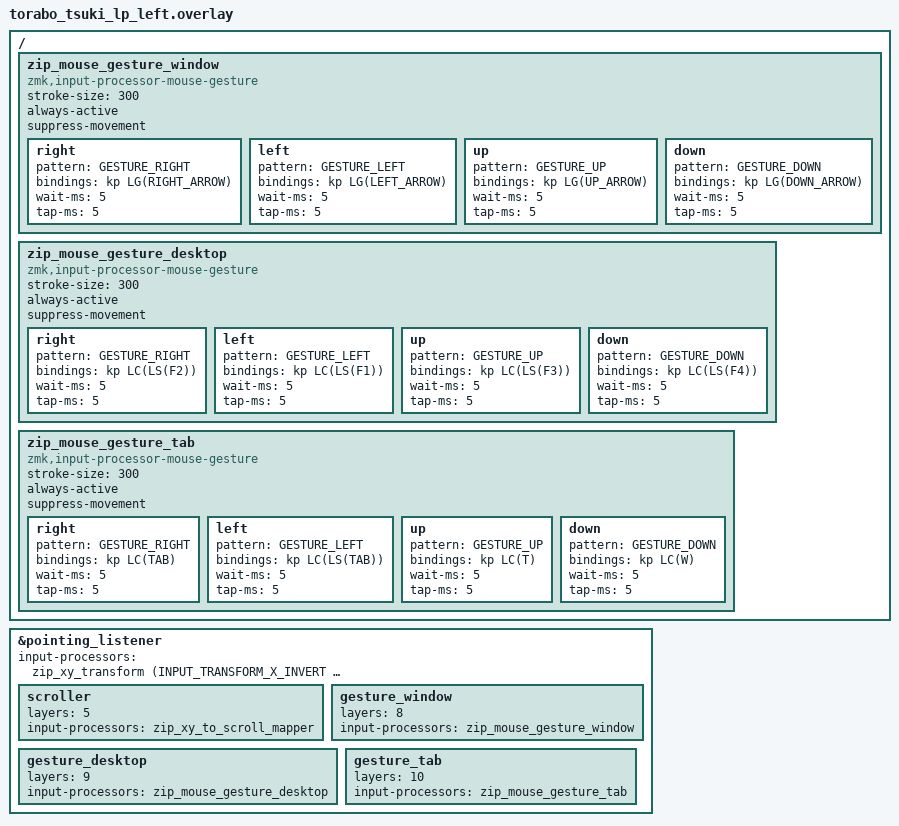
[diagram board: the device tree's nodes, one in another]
#include "torabo_tsuki_lp.dtsi"
#include <input/processors.dtsi>
#include <dt-bindings/zmk/input_transform.h>
#include <dt-bindings/zmk/mouse-gesture.h>
#include <dt-bindings/zmk/keys.h>
#include <behaviors.dtsi>

/ {
    // roBa-compatible trackball gestures (window snap / virtual desktop / tab switching),
    // reimplemented via kot149/zmk-mouse-gesture since this shield's paw3222 driver has
    // no built-in gesture support like roBa's pmw3610 driver. Wired to layers 8/9/10 below.
    // NOTE: keys.h's single-arg RC() (Right Ctrl) collides with matrix_transform.h's RC(row,col)
    // used inside torabo_tsuki_lp.dtsi, so these includes must come AFTER that #include, not before.
    zip_mouse_gesture_window: zip_mouse_gesture_window {
        compatible = "zmk,input-processor-mouse-gesture";
        #input-processor-cells = <0>;
        stroke-size = <300>;
        always-active;
        suppress-movement;

        right {
            pattern = <GESTURE_RIGHT>;
            bindings = <&kp LG(RIGHT_ARROW)>;
            wait-ms = <5>;
            tap-ms = <5>;
        };
        left {
            pattern = <GESTURE_LEFT>;
            bindings = <&kp LG(LEFT_ARROW)>;
            wait-ms = <5>;
            tap-ms = <5>;
        };
        up {
            pattern = <GESTURE_UP>;
            bindings = <&kp LG(UP_ARROW)>;
            wait-ms = <5>;
            tap-ms = <5>;
        };
        down {
            pattern = <GESTURE_DOWN>;
            bindings = <&kp LG(DOWN_ARROW)>;
            wait-ms = <5>;
            tap-ms = <5>;
        };
    };

    zip_mouse_gesture_desktop: zip_mouse_gesture_desktop {
        compatible = "zmk,input-processor-mouse-gesture";
        #input-processor-cells = <0>;
        stroke-size = <300>;
        always-active;
        suppress-movement;

        right {
            pattern = <GESTURE_RIGHT>;
            bindings = <&kp LC(LS(F2))>;
            wait-ms = <5>;
            tap-ms = <5>;
        };
        left {
            pattern = <GESTURE_LEFT>;
            bindings = <&kp LC(LS(F1))>;
            wait-ms = <5>;
            tap-ms = <5>;
        };
        up {
            pattern = <GESTURE_UP>;
            bindings = <&kp LC(LS(F3))>;
            wait-ms = <5>;
            tap-ms = <5>;
        };
        down {
            pattern = <GESTURE_DOWN>;
            bindings = <&kp LC(LS(F4))>;
            wait-ms = <5>;
            tap-ms = <5>;
        };
    };

    zip_mouse_gesture_tab: zip_mouse_gesture_tab {
        compatible = "zmk,input-processor-mouse-gesture";
        #input-processor-cells = <0>;
        stroke-size = <300>;
        always-active;
        suppress-movement;

        right {
            pattern = <GESTURE_RIGHT>;
            bindings = <&kp LC(TAB)>;
            wait-ms = <5>;
            tap-ms = <5>;
        };
        left {
            pattern = <GESTURE_LEFT>;
            bindings = <&kp LC(LS(TAB))>;
            wait-ms = <5>;
            tap-ms = <5>;
        };
        up {
            pattern = <GESTURE_UP>;
            bindings = <&kp LC(T)>;
            wait-ms = <5>;
            tap-ms = <5>;
        };
        down {
            pattern = <GESTURE_DOWN>;
            bindings = <&kp LC(W)>;
            wait-ms = <5>;
            tap-ms = <5>;
        };
    };
};

&pointing_listener {
    input-processors = <&zip_xy_transform (INPUT_TRANSFORM_X_INVERT | INPUT_TRANSFORM_Y_INVERT)>;

    scroller {
        layers = <5>;
        input-processors = <&zip_xy_to_scroll_mapper>;
    };

    gesture_window {
        layers = <8>;
        input-processors = <&zip_mouse_gesture_window>;
    };

    gesture_desktop {
        layers = <9>;
        input-processors = <&zip_mouse_gesture_desktop>;
    };

    gesture_tab {
        layers = <10>;
        input-processors = <&zip_mouse_gesture_tab>;
    };
};
